# STM32F303x register map
File version: 1.0
Registers are 32-bit, read-write, reset 0x0 unless marked. A register's access mark holds for its fields unless they carry their own. Offsets are from the block's base; [hi:lo] are bit positions; {n}, {i} and the like mark numbered series.

## SYSCFG — System configuration controller
Base 0x40010000
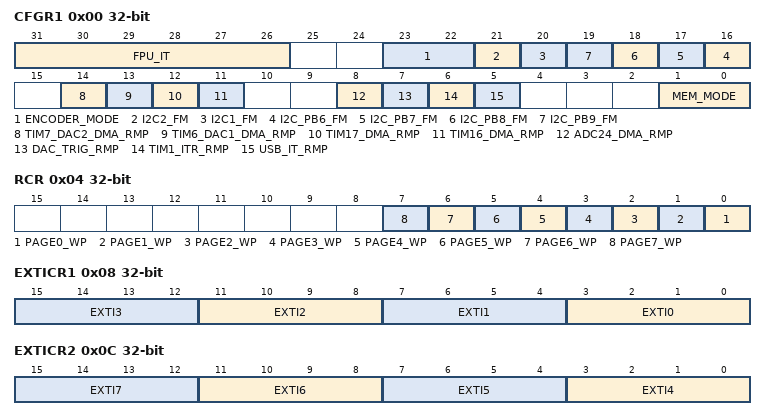
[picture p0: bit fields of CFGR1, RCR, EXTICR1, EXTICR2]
0x00 CFGR1 — configuration register 1
  [31:26] FPU_IT — Interrupt enable bits from FPU
  [23:22] ENCODER_MODE
  [21] I2C2_FM — I2C2 Fast Mode Plus
  [20] I2C1_FM — I2C1 Fast Mode Plus
  [n+10] I2C_PB{n}_FM (n=6..9) — Fast Mode Plus (FM+) driving capability activation bits.
  [14] TIM7_DAC2_DMA_RMP — TIM7 and DAC2 DMA request remapping bit
  [13] TIM6_DAC1_DMA_RMP — TIM6 and DAC1 DMA request remapping bit
  [12] TIM17_DMA_RMP — TIM17 DMA request remapping bit
  [11] TIM16_DMA_RMP — TIM16 DMA request remapping bit
  [8] ADC24_DMA_RMP — ADC24 DMA remapping bit
  [7] DAC_TRIG_RMP — DAC trigger remap (when TSEL = 001)
  [6] TIM1_ITR_RMP — Timer 1 ITR3 selection
  [5] USB_IT_RMP — USB interrupt remap
  [1:0] MEM_MODE — Memory mapping selection bits
0x04 RCR — CCM SRAM protection register
  [n] PAGE{n}_WP (n=0..7) — CCM SRAM page write protection bit
0x08 EXTICR1 — external interrupt configuration register 1
  [all] fields
    0=PortA; 1=PortB; 2=PortC; 3=PortD; 4=PortE
  [4n+3:4n] EXTI{n} (n=0..3) — EXTI {n} configuration bits
0x0C EXTICR2 — external interrupt configuration register 2
  [all] fields
    0=PortA; 1=PortB; 2=PortC; 3=PortD; 4=PortE
  [4n-13:4n-16] EXTI{n} (n=4..7) — EXTI {n} configuration bits
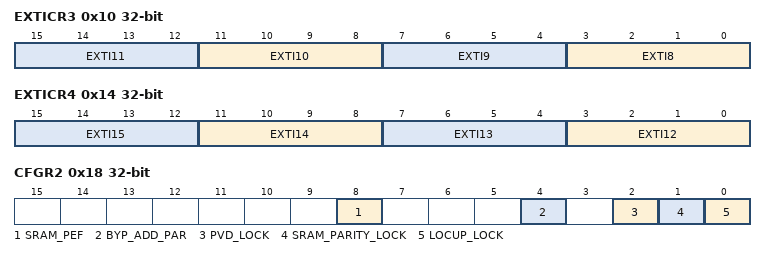
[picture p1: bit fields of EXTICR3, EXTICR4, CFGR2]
0x10 EXTICR3 — external interrupt configuration register 3
  [all] fields
    0=PortA; 1=PortB; 2=PortC; 3=PortD; 4=PortE
  [4n-29:4n-32] EXTI{n} (n=8..11) — EXTI {n} configuration bits
0x14 EXTICR4 — external interrupt configuration register 4
  [all] fields
    0=PortA; 1=PortB; 2=PortC; 3=PortD; 4=PortE
  [4n-45:4n-48] EXTI{n} (n=12..15) — EXTI {n} configuration bits
0x18 CFGR2 — configuration register 2
  [8] SRAM_PEF — SRAM parity flag
  [4] BYP_ADD_PAR — Bypass address bit 29 in parity calculation
  [2] PVD_LOCK — PVD lock enable bit
  [1] SRAM_PARITY_LOCK — SRAM parity lock bit
  [0] LOCUP_LOCK — Cortex-M0 LOCKUP bit enable bit

## OPAMP — Operational amplifier
Base 0x40010038
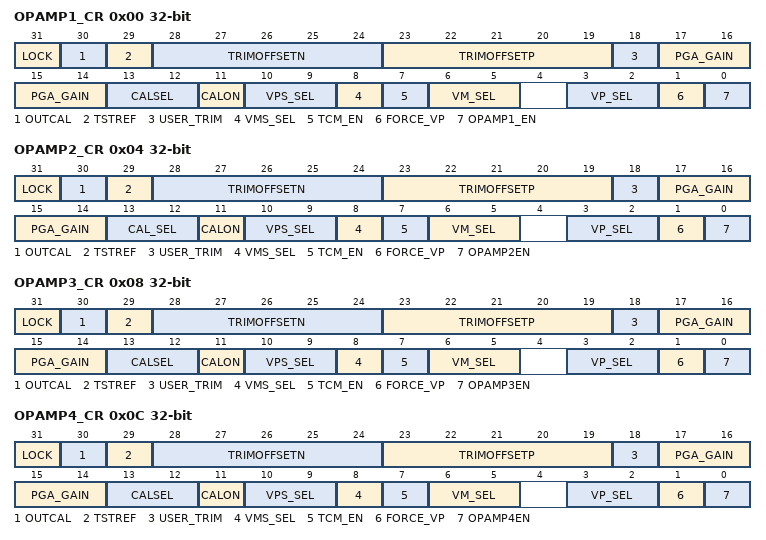
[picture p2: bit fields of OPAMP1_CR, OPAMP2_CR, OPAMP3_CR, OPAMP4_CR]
0x00 OPAMP1_CR access per field — OPAMP1 control register
  [31] LOCK rw — OPAMP 1 lock
  [30] OUTCAL ro — OPAMP 1 ouput status flag
  [29] TSTREF rw
  [28:24] TRIMOFFSETN rw — Offset trimming value (NMOS)
  [23:19] TRIMOFFSETP rw — Offset trimming value (PMOS)
  [18] USER_TRIM rw — User trimming enable
  [17:14] PGA_GAIN rw — Gain in PGA mode
  [13:12] CALSEL rw — Calibration selection
  [11] CALON rw — Calibration mode enable
  [10:9] VPS_SEL rw — OPAMP1 Non inverting input secondary selection
  [8] VMS_SEL rw — OPAMP1 inverting input secondary selection
  [7] TCM_EN rw — Timer controlled Mux mode enable
  [6:5] VM_SEL rw — OPAMP1 inverting input selection
  [3:2] VP_SEL rw — OPAMP1 Non inverting input selection
  [1] FORCE_VP rw
  [0] OPAMP1_EN rw — OPAMP1 enable
0x04 OPAMP2_CR access per field — OPAMP2 control register
  [31] LOCK rw — OPAMP 2 lock
  [30] OUTCAL ro — OPAMP 2 ouput status flag
  [29] TSTREF rw
  [28:24] TRIMOFFSETN rw — Offset trimming value (NMOS)
  [23:19] TRIMOFFSETP rw — Offset trimming value (PMOS)
  [18] USER_TRIM rw — User trimming enable
  [17:14] PGA_GAIN rw — Gain in PGA mode
  [13:12] CAL_SEL rw — Calibration selection
  [11] CALON rw — Calibration mode enable
  [10:9] VPS_SEL rw — OPAMP2 Non inverting input secondary selection
  [8] VMS_SEL rw — OPAMP2 inverting input secondary selection
  [7] TCM_EN rw — Timer controlled Mux mode enable
  [6:5] VM_SEL rw — OPAMP2 inverting input selection
  [3:2] VP_SEL rw — OPAMP2 Non inverting input selection
  [1] FORCE_VP rw
  [0] OPAMP2EN rw — OPAMP2 enable
0x08 OPAMP3_CR access per field — OPAMP3 control register
  [31] LOCK rw — OPAMP 3 lock
  [30] OUTCAL ro — OPAMP 3 ouput status flag
  [29] TSTREF rw
  [28:24] TRIMOFFSETN rw — Offset trimming value (NMOS)
  [23:19] TRIMOFFSETP rw — Offset trimming value (PMOS)
  [18] USER_TRIM rw — User trimming enable
  [17:14] PGA_GAIN rw — Gain in PGA mode
  [13:12] CALSEL rw — Calibration selection
  [11] CALON rw — Calibration mode enable
  [10:9] VPS_SEL rw — OPAMP3 Non inverting input secondary selection
  [8] VMS_SEL rw — OPAMP3 inverting input secondary selection
  [7] TCM_EN rw — Timer controlled Mux mode enable
  [6:5] VM_SEL rw — OPAMP3 inverting input selection
  [3:2] VP_SEL rw — OPAMP3 Non inverting input selection
  [1] FORCE_VP rw
  [0] OPAMP3EN rw — OPAMP3 enable
0x0C OPAMP4_CR access per field — OPAMP4 control register
  [31] LOCK rw — OPAMP 4 lock
  [30] OUTCAL ro — OPAMP 4 ouput status flag
  [29] TSTREF rw
  [28:24] TRIMOFFSETN rw — Offset trimming value (NMOS)
  [23:19] TRIMOFFSETP rw — Offset trimming value (PMOS)
  [18] USER_TRIM rw — User trimming enable
  [17:14] PGA_GAIN rw — Gain in PGA mode
  [13:12] CALSEL rw — Calibration selection
  [11] CALON rw — Calibration mode enable
  [10:9] VPS_SEL rw — OPAMP4 Non inverting input secondary selection
  [8] VMS_SEL rw — OPAMP4 inverting input secondary selection
  [7] TCM_EN rw — Timer controlled Mux mode enable
  [6:5] VM_SEL rw — OPAMP4 inverting input selection
  [3:2] VP_SEL rw — OPAMP4 Non inverting input selection
  [1] FORCE_VP rw
  [0] OPAMP4EN rw — OPAMP4 enable
